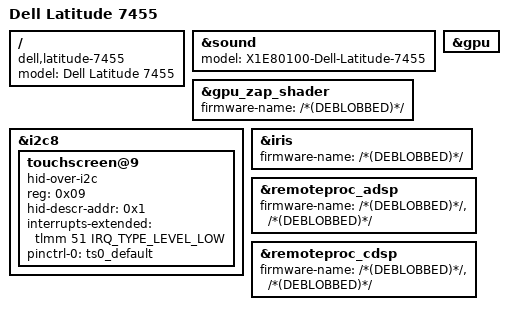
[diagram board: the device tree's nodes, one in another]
// SPDX-License-Identifier: BSD-3-Clause
/*
 * Copyright (c) 2025 Val Packett <val@packett.cool>
 */
/dts-v1/;

#include "x1e80100.dtsi"
#include "x1-dell-thena.dtsi"

/ {
	model = "Dell Latitude 7455";
	compatible = "dell,latitude-7455", "qcom,x1e80100";
};

&sound {
	model = "X1E80100-Dell-Latitude-7455";
};

&gpu {
	status = "okay";
};

&gpu_zap_shader {
	firmware-name = "/*(DEBLOBBED)*/";
};

&i2c8 {
	/* LXST2021 */
	touchscreen@9 {
		compatible = "hid-over-i2c";
		reg = <0x09>;

		hid-descr-addr = <0x1>;
		interrupts-extended = <&tlmm 51 IRQ_TYPE_LEVEL_LOW>;

		pinctrl-0 = <&ts0_default>;
		pinctrl-names = "default";
	};
};

&iris {
	firmware-name = "/*(DEBLOBBED)*/";
	status = "okay";
};

&remoteproc_adsp {
	firmware-name = "/*(DEBLOBBED)*/",
			"/*(DEBLOBBED)*/";

	status = "okay";
};

&remoteproc_cdsp {
	firmware-name = "/*(DEBLOBBED)*/",
			"/*(DEBLOBBED)*/";

	status = "okay";
};
